# ESP32-S31 register map
Vendor: ESPRESSIF SYSTEMS (SHANGHAI) CO., LTD.; Series: ESP32 S-Series; File version: 1
CPU: RV32IMAFC r0p0, little endian, no MPU, FPU, 0 interrupt priority bits
Address unit: 32 bits
Registers are 32-bit, read-write, reset 0x0 unless marked. A register's access mark holds for its fields unless they carry their own. Offsets are from the block's base; [hi:lo] are bit positions; lines under a group give offsets from that group; {n}, {i} and the like mark numbered series.

## SOC_ETM (part 1 of 4) — Event Task Matrix
Base 0x20393000
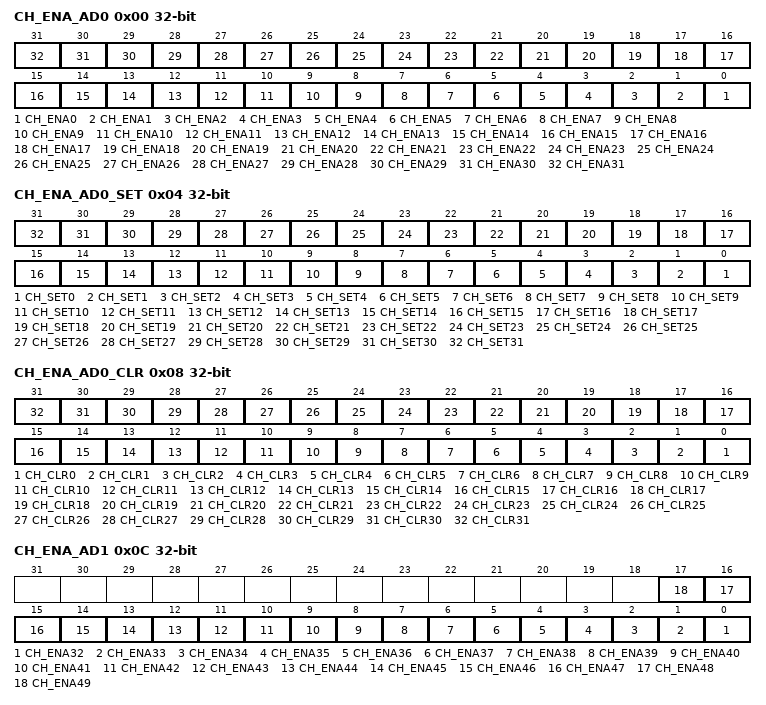
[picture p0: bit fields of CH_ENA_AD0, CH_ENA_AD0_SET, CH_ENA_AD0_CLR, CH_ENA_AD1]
0x00 CH_ENA_AD0 — Channel enable status register
  [n] CH_ENA{n} (n=0..31) — Represents ch{n} enable status.\\0: Disable\\1: Enable
0x04 CH_ENA_AD0_SET wo — Channel enable set register
  [n] CH_SET{n} (n=0..31) — Configures whether or not to enable ch{n}.\\0: Invalid, No effect\\1: Enable
0x08 CH_ENA_AD0_CLR wo — Channel enable clear register
  [n] CH_CLR{n} (n=0..31) — Configures whether or not to clear ch{n} enable.\\0: Invalid, No effect\\1: Clear
0x0C CH_ENA_AD1 — Channel enable status register
  [n-32] CH_ENA{n} (n=32..49) — Represents ch{n} enable status.\\0: Disable\\1: Enable
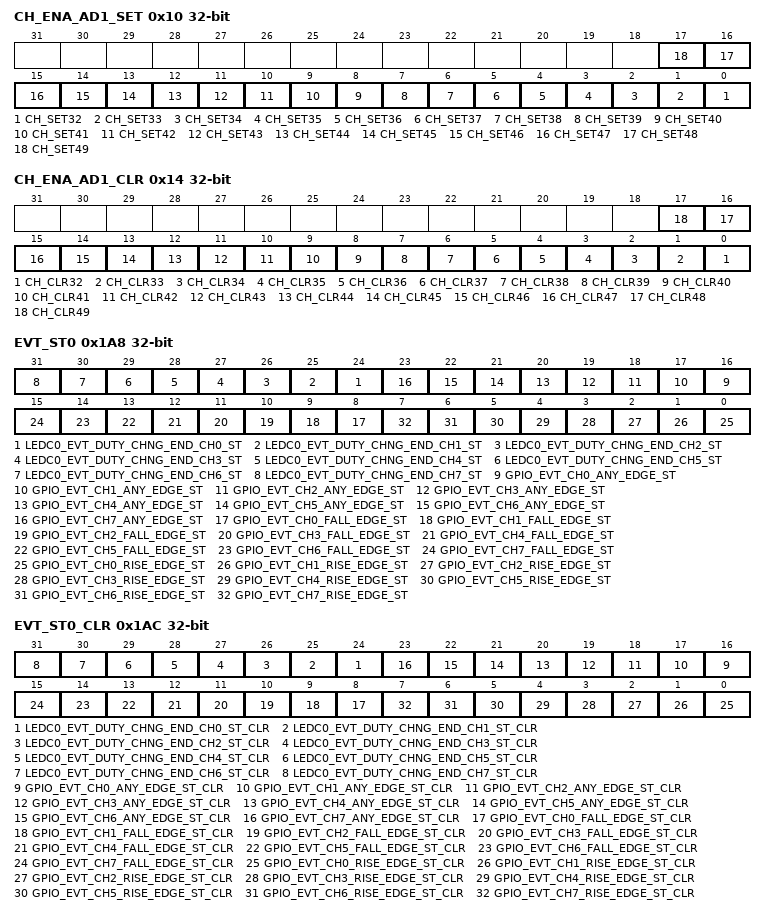
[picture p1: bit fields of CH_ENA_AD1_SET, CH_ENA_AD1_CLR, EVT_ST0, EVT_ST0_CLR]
0x10 CH_ENA_AD1_SET wo — Channel enable set register
  [n-32] CH_SET{n} (n=32..49) — Configures whether or not to enable ch{n}.\\0: Invalid, No effect\\1: Enable
0x14 CH_ENA_AD1_CLR wo — Channel enable clear register
  [n-32] CH_CLR{n} (n=32..49) — Configures whether or not to clear ch{n} enable.\\0: Invalid, No effect\\1: Clear
{0x18+8i} CH{i} (i=0..49) group — Cluster CH{i}, containing CH*_EVT_ID, CH*_TASK_ID
  0x00 EVT_ID — Channel0 event id register
    [8:0] EVT_ID — Configures ch%s_evt_id
  0x04 TASK_ID — Channel0 task id register
    [8:0] TASK_ID — Configures ch%s_task_id
0x1A8 EVT_ST0 — Events trigger status register
  [n+24] LEDC0_EVT_DUTY_CHNG_END_CH{n}_ST (n=0..7) — Represents LEDC0_evt_duty_chng_end_ch{n} trigger status.\\0: Not triggered\\1: Triggered
  [n+16] GPIO_EVT_CH{n}_ANY_EDGE_ST (n=0..7) — Represents GPIO_evt_ch{n}_any_edge trigger status.\\0: Not triggered\\1: Triggered
  [n+8] GPIO_EVT_CH{n}_FALL_EDGE_ST (n=0..7) — Represents GPIO_evt_ch{n}_fall_edge trigger status.\\0: Not triggered\\1: Triggered
  [n] GPIO_EVT_CH{n}_RISE_EDGE_ST (n=0..7) — Represents GPIO_evt_ch{n}_rise_edge trigger status.\\0: Not triggered\\1: Triggered
0x1AC EVT_ST0_CLR wo — Events trigger status clear register
  [n+24] LEDC0_EVT_DUTY_CHNG_END_CH{n}_ST_CLR (n=0..7) — Configures whether or not to clear LEDC0_evt_duty_chng_end_ch{n} trigger status.\\0: Invalid, No effect\\1: Clear
  [n+16] GPIO_EVT_CH{n}_ANY_EDGE_ST_CLR (n=0..7) — Configures whether or not to clear GPIO_evt_ch{n}_any_edge trigger status.\\0: Invalid, No effect\\1: Clear
  [n+8] GPIO_EVT_CH{n}_FALL_EDGE_ST_CLR (n=0..7) — Configures whether or not to clear GPIO_evt_ch{n}_fall_edge trigger status.\\0: Invalid, No effect\\1: Clear
  [n] GPIO_EVT_CH{n}_RISE_EDGE_ST_CLR (n=0..7) — Configures whether or not to clear GPIO_evt_ch{n}_rise_edge trigger status.\\0: Invalid, No effect\\1: Clear
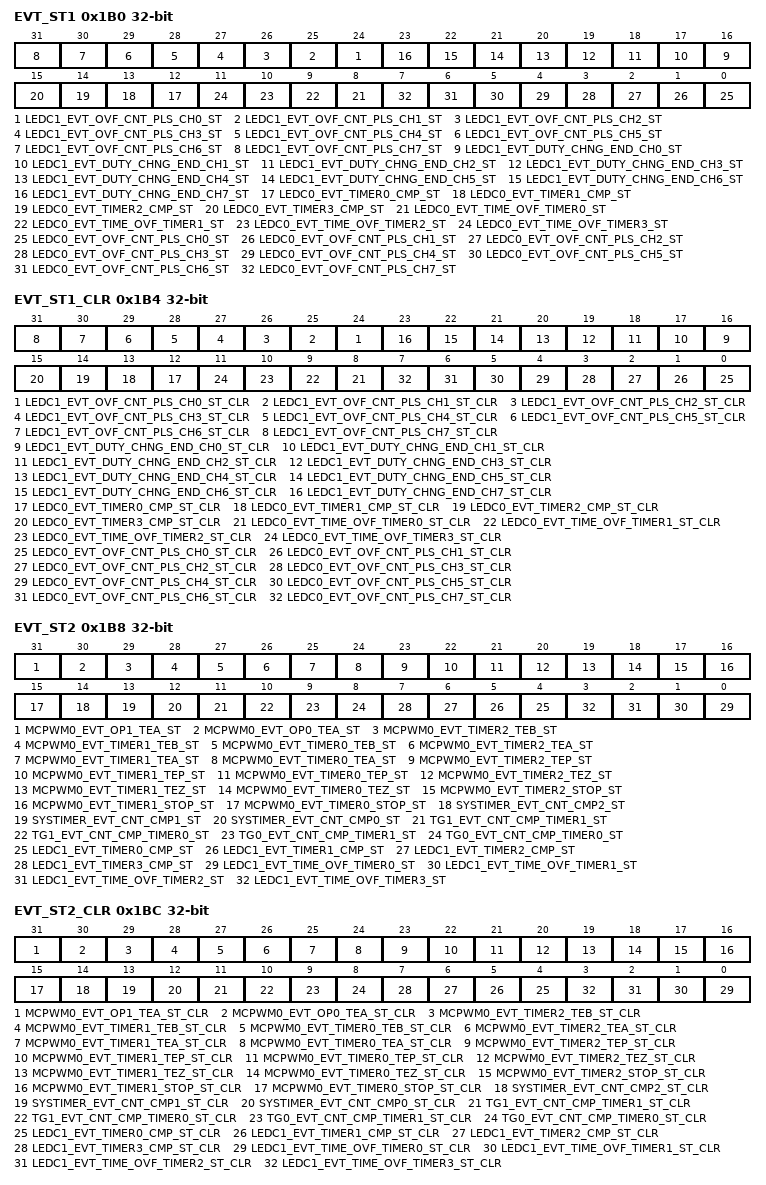
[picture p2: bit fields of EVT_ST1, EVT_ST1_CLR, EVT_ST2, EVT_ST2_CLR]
0x1B0 EVT_ST1 — Events trigger status register
  [n+24] LEDC1_EVT_OVF_CNT_PLS_CH{n}_ST (n=0..7) — Represents LEDC1_evt_ovf_cnt_pls_ch{n} trigger status.\\0: Not triggered\\1: Triggered
  [n+16] LEDC1_EVT_DUTY_CHNG_END_CH{n}_ST (n=0..7) — Represents LEDC1_evt_duty_chng_end_ch{n} trigger status.\\0: Not triggered\\1: Triggered
  [n+12] LEDC0_EVT_TIMER{n}_CMP_ST (n=0..3) — Represents LEDC0_evt_timer{n}_cmp trigger status.\\0: Not triggered\\1: Triggered
  [n+8] LEDC0_EVT_TIME_OVF_TIMER{n}_ST (n=0..3) — Represents LEDC0_evt_time_ovf_timer{n} trigger status.\\0: Not triggered\\1: Triggered
  [n] LEDC0_EVT_OVF_CNT_PLS_CH{n}_ST (n=0..7) — Represents LEDC0_evt_ovf_cnt_pls_ch{n} trigger status.\\0: Not triggered\\1: Triggered
0x1B4 EVT_ST1_CLR wo — Events trigger status clear register
  [n+24] LEDC1_EVT_OVF_CNT_PLS_CH{n}_ST_CLR (n=0..7) — Configures whether or not to clear LEDC1_evt_ovf_cnt_pls_ch{n} trigger status.\\0: Invalid, No effect\\1: Clear
  [n+16] LEDC1_EVT_DUTY_CHNG_END_CH{n}_ST_CLR (n=0..7) — Configures whether or not to clear LEDC1_evt_duty_chng_end_ch{n} trigger status.\\0: Invalid, No effect\\1: Clear
  [n+12] LEDC0_EVT_TIMER{n}_CMP_ST_CLR (n=0..3) — Configures whether or not to clear LEDC0_evt_timer{n}_cmp trigger status.\\0: Invalid, No effect\\1: Clear
  [n+8] LEDC0_EVT_TIME_OVF_TIMER{n}_ST_CLR (n=0..3) — Configures whether or not to clear LEDC0_evt_time_ovf_timer{n} trigger status.\\0: Invalid, No effect\\1: Clear
  [n] LEDC0_EVT_OVF_CNT_PLS_CH{n}_ST_CLR (n=0..7) — Configures whether or not to clear LEDC0_evt_ovf_cnt_pls_ch{n} trigger status.\\0: Invalid, No effect\\1: Clear
0x1B8 EVT_ST2 — Events trigger status register
  [31] MCPWM0_EVT_OP1_TEA_ST — Represents MCPWM0_evt_op1_tea trigger status.\\0: Not triggered\\1: Triggered
  [30] MCPWM0_EVT_OP0_TEA_ST — Represents MCPWM0_evt_op0_tea trigger status.\\0: Not triggered\\1: Triggered
  [29] MCPWM0_EVT_TIMER2_TEB_ST — Represents MCPWM0_evt_timer2_teb trigger status.\\0: Not triggered\\1: Triggered
  [28] MCPWM0_EVT_TIMER1_TEB_ST — Represents MCPWM0_evt_timer1_teb trigger status.\\0: Not triggered\\1: Triggered
  [27] MCPWM0_EVT_TIMER0_TEB_ST — Represents MCPWM0_evt_timer0_teb trigger status.\\0: Not triggered\\1: Triggered
  [26] MCPWM0_EVT_TIMER2_TEA_ST — Represents MCPWM0_evt_timer2_tea trigger status.\\0: Not triggered\\1: Triggered
  [25] MCPWM0_EVT_TIMER1_TEA_ST — Represents MCPWM0_evt_timer1_tea trigger status.\\0: Not triggered\\1: Triggered
  [24] MCPWM0_EVT_TIMER0_TEA_ST — Represents MCPWM0_evt_timer0_tea trigger status.\\0: Not triggered\\1: Triggered
  [23] MCPWM0_EVT_TIMER2_TEP_ST — Represents MCPWM0_evt_timer2_tep trigger status.\\0: Not triggered\\1: Triggered
  [22] MCPWM0_EVT_TIMER1_TEP_ST — Represents MCPWM0_evt_timer1_tep trigger status.\\0: Not triggered\\1: Triggered
  [21] MCPWM0_EVT_TIMER0_TEP_ST — Represents MCPWM0_evt_timer0_tep trigger status.\\0: Not triggered\\1: Triggered
  [20] MCPWM0_EVT_TIMER2_TEZ_ST — Represents MCPWM0_evt_timer2_tez trigger status.\\0: Not triggered\\1: Triggered
  [19] MCPWM0_EVT_TIMER1_TEZ_ST — Represents MCPWM0_evt_timer1_tez trigger status.\\0: Not triggered\\1: Triggered
  [18] MCPWM0_EVT_TIMER0_TEZ_ST — Represents MCPWM0_evt_timer0_tez trigger status.\\0: Not triggered\\1: Triggered
  [17] MCPWM0_EVT_TIMER2_STOP_ST — Represents MCPWM0_evt_timer2_stop trigger status.\\0: Not triggered\\1: Triggered
  [16] MCPWM0_EVT_TIMER1_STOP_ST — Represents MCPWM0_evt_timer1_stop trigger status.\\0: Not triggered\\1: Triggered
  [15] MCPWM0_EVT_TIMER0_STOP_ST — Represents MCPWM0_evt_timer0_stop trigger status.\\0: Not triggered\\1: Triggered
  [14] SYSTIMER_EVT_CNT_CMP2_ST — Represents SYSTIMER_evt_cnt_cmp2 trigger status.\\0: Not triggered\\1: Triggered
  [13] SYSTIMER_EVT_CNT_CMP1_ST — Represents SYSTIMER_evt_cnt_cmp1 trigger status.\\0: Not triggered\\1: Triggered
  [12] SYSTIMER_EVT_CNT_CMP0_ST — Represents SYSTIMER_evt_cnt_cmp0 trigger status.\\0: Not triggered\\1: Triggered
  [11] TG1_EVT_CNT_CMP_TIMER1_ST — Represents TG1_evt_cnt_cmp_timer1 trigger status.\\0: Not triggered\\1: Triggered
  [10] TG1_EVT_CNT_CMP_TIMER0_ST — Represents TG1_evt_cnt_cmp_timer0 trigger status.\\0: Not triggered\\1: Triggered
  [9] TG0_EVT_CNT_CMP_TIMER1_ST — Represents TG0_evt_cnt_cmp_timer1 trigger status.\\0: Not triggered\\1: Triggered
  [8] TG0_EVT_CNT_CMP_TIMER0_ST — Represents TG0_evt_cnt_cmp_timer0 trigger status.\\0: Not triggered\\1: Triggered
  [n+4] LEDC1_EVT_TIMER{n}_CMP_ST (n=0..3) — Represents LEDC1_evt_timer{n}_cmp trigger status.\\0: Not triggered\\1: Triggered
  [n] LEDC1_EVT_TIME_OVF_TIMER{n}_ST (n=0..3) — Represents LEDC1_evt_time_ovf_timer{n} trigger status.\\0: Not triggered\\1: Triggered
0x1BC EVT_ST2_CLR wo — Events trigger status clear register
  [31] MCPWM0_EVT_OP1_TEA_ST_CLR — Configures whether or not to clear MCPWM0_evt_op1_tea trigger status.\\0: Invalid, No effect\\1: Clear
  [30] MCPWM0_EVT_OP0_TEA_ST_CLR — Configures whether or not to clear MCPWM0_evt_op0_tea trigger status.\\0: Invalid, No effect\\1: Clear
  [29] MCPWM0_EVT_TIMER2_TEB_ST_CLR — Configures whether or not to clear MCPWM0_evt_timer2_teb trigger status.\\0: Invalid, No effect\\1: Clear
  [28] MCPWM0_EVT_TIMER1_TEB_ST_CLR — Configures whether or not to clear MCPWM0_evt_timer1_teb trigger status.\\0: Invalid, No effect\\1: Clear
  [27] MCPWM0_EVT_TIMER0_TEB_ST_CLR — Configures whether or not to clear MCPWM0_evt_timer0_teb trigger status.\\0: Invalid, No effect\\1: Clear
  [26] MCPWM0_EVT_TIMER2_TEA_ST_CLR — Configures whether or not to clear MCPWM0_evt_timer2_tea trigger status.\\0: Invalid, No effect\\1: Clear
  [25] MCPWM0_EVT_TIMER1_TEA_ST_CLR — Configures whether or not to clear MCPWM0_evt_timer1_tea trigger status.\\0: Invalid, No effect\\1: Clear
  [24] MCPWM0_EVT_TIMER0_TEA_ST_CLR — Configures whether or not to clear MCPWM0_evt_timer0_tea trigger status.\\0: Invalid, No effect\\1: Clear
  [23] MCPWM0_EVT_TIMER2_TEP_ST_CLR — Configures whether or not to clear MCPWM0_evt_timer2_tep trigger status.\\0: Invalid, No effect\\1: Clear
  [22] MCPWM0_EVT_TIMER1_TEP_ST_CLR — Configures whether or not to clear MCPWM0_evt_timer1_tep trigger status.\\0: Invalid, No effect\\1: Clear
  [21] MCPWM0_EVT_TIMER0_TEP_ST_CLR — Configures whether or not to clear MCPWM0_evt_timer0_tep trigger status.\\0: Invalid, No effect\\1: Clear
  [20] MCPWM0_EVT_TIMER2_TEZ_ST_CLR — Configures whether or not to clear MCPWM0_evt_timer2_tez trigger status.\\0: Invalid, No effect\\1: Clear
  [19] MCPWM0_EVT_TIMER1_TEZ_ST_CLR — Configures whether or not to clear MCPWM0_evt_timer1_tez trigger status.\\0: Invalid, No effect\\1: Clear
  [18] MCPWM0_EVT_TIMER0_TEZ_ST_CLR — Configures whether or not to clear MCPWM0_evt_timer0_tez trigger status.\\0: Invalid, No effect\\1: Clear
  [17] MCPWM0_EVT_TIMER2_STOP_ST_CLR — Configures whether or not to clear MCPWM0_evt_timer2_stop trigger status.\\0: Invalid, No effect\\1: Clear
  [16] MCPWM0_EVT_TIMER1_STOP_ST_CLR — Configures whether or not to clear MCPWM0_evt_timer1_stop trigger status.\\0: Invalid, No effect\\1: Clear
  [15] MCPWM0_EVT_TIMER0_STOP_ST_CLR — Configures whether or not to clear MCPWM0_evt_timer0_stop trigger status.\\0: Invalid, No effect\\1: Clear
  [14] SYSTIMER_EVT_CNT_CMP2_ST_CLR — Configures whether or not to clear SYSTIMER_evt_cnt_cmp2 trigger status.\\0: Invalid, No effect\\1: Clear
  [13] SYSTIMER_EVT_CNT_CMP1_ST_CLR — Configures whether or not to clear SYSTIMER_evt_cnt_cmp1 trigger status.\\0: Invalid, No effect\\1: Clear
  [12] SYSTIMER_EVT_CNT_CMP0_ST_CLR — Configures whether or not to clear SYSTIMER_evt_cnt_cmp0 trigger status.\\0: Invalid, No effect\\1: Clear
  [11] TG1_EVT_CNT_CMP_TIMER1_ST_CLR — Configures whether or not to clear TG1_evt_cnt_cmp_timer1 trigger status.\\0: Invalid, No effect\\1: Clear
  [10] TG1_EVT_CNT_CMP_TIMER0_ST_CLR — Configures whether or not to clear TG1_evt_cnt_cmp_timer0 trigger status.\\0: Invalid, No effect\\1: Clear
  [9] TG0_EVT_CNT_CMP_TIMER1_ST_CLR — Configures whether or not to clear TG0_evt_cnt_cmp_timer1 trigger status.\\0: Invalid, No effect\\1: Clear
  [8] TG0_EVT_CNT_CMP_TIMER0_ST_CLR — Configures whether or not to clear TG0_evt_cnt_cmp_timer0 trigger status.\\0: Invalid, No effect\\1: Clear
  [n+4] LEDC1_EVT_TIMER{n}_CMP_ST_CLR (n=0..3) — Configures whether or not to clear LEDC1_evt_timer{n}_cmp trigger status.\\0: Invalid, No effect\\1: Clear
  [n] LEDC1_EVT_TIME_OVF_TIMER{n}_ST_CLR (n=0..3) — Configures whether or not to clear LEDC1_evt_time_ovf_timer{n} trigger status.\\0: Invalid, No effect\\1: Clear
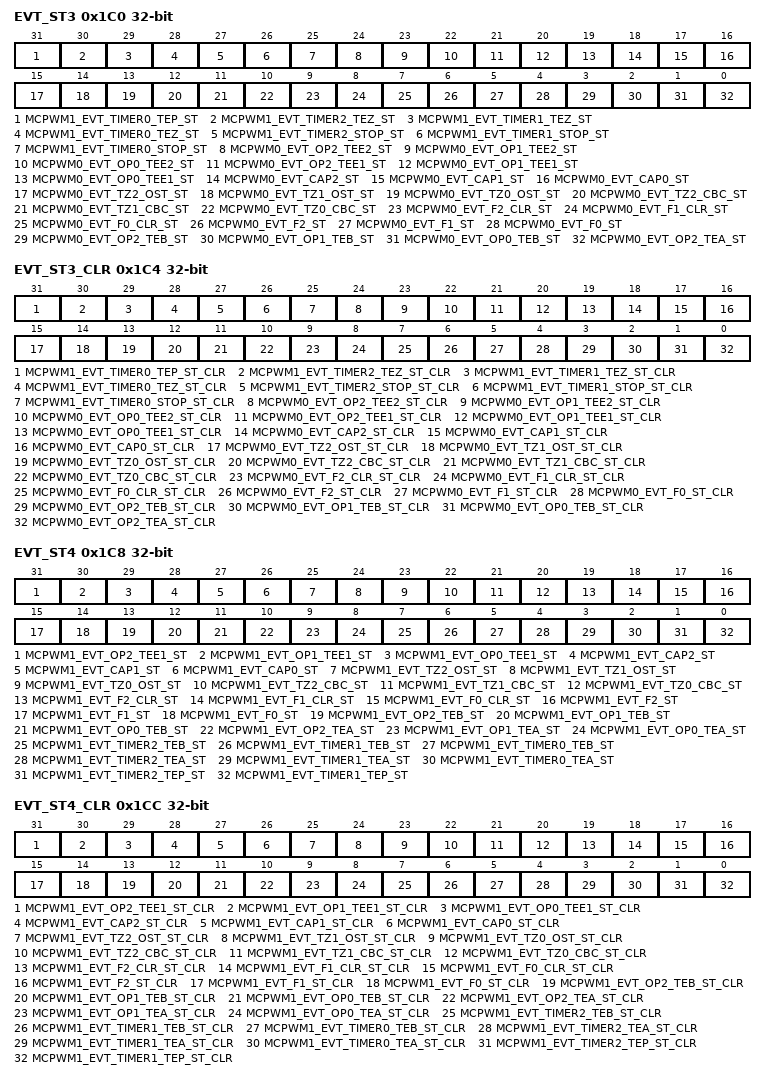
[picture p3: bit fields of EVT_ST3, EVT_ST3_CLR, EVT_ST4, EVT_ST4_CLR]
0x1C0 EVT_ST3 — Events trigger status register
  [31] MCPWM1_EVT_TIMER0_TEP_ST — Represents MCPWM1_evt_timer0_tep trigger status.\\0: Not triggered\\1: Triggered
  [30] MCPWM1_EVT_TIMER2_TEZ_ST — Represents MCPWM1_evt_timer2_tez trigger status.\\0: Not triggered\\1: Triggered
  [29] MCPWM1_EVT_TIMER1_TEZ_ST — Represents MCPWM1_evt_timer1_tez trigger status.\\0: Not triggered\\1: Triggered
  [28] MCPWM1_EVT_TIMER0_TEZ_ST — Represents MCPWM1_evt_timer0_tez trigger status.\\0: Not triggered\\1: Triggered
  [27] MCPWM1_EVT_TIMER2_STOP_ST — Represents MCPWM1_evt_timer2_stop trigger status.\\0: Not triggered\\1: Triggered
  [26] MCPWM1_EVT_TIMER1_STOP_ST — Represents MCPWM1_evt_timer1_stop trigger status.\\0: Not triggered\\1: Triggered
  [25] MCPWM1_EVT_TIMER0_STOP_ST — Represents MCPWM1_evt_timer0_stop trigger status.\\0: Not triggered\\1: Triggered
  [24] MCPWM0_EVT_OP2_TEE2_ST — Represents MCPWM0_evt_op2_tee2 trigger status.\\0: Not triggered\\1: Triggered
  [23] MCPWM0_EVT_OP1_TEE2_ST — Represents MCPWM0_evt_op1_tee2 trigger status.\\0: Not triggered\\1: Triggered
  [22] MCPWM0_EVT_OP0_TEE2_ST — Represents MCPWM0_evt_op0_tee2 trigger status.\\0: Not triggered\\1: Triggered
  [21] MCPWM0_EVT_OP2_TEE1_ST — Represents MCPWM0_evt_op2_tee1 trigger status.\\0: Not triggered\\1: Triggered
  [20] MCPWM0_EVT_OP1_TEE1_ST — Represents MCPWM0_evt_op1_tee1 trigger status.\\0: Not triggered\\1: Triggered
  [19] MCPWM0_EVT_OP0_TEE1_ST — Represents MCPWM0_evt_op0_tee1 trigger status.\\0: Not triggered\\1: Triggered
  [18] MCPWM0_EVT_CAP2_ST — Represents MCPWM0_evt_cap2 trigger status.\\0: Not triggered\\1: Triggered
  [17] MCPWM0_EVT_CAP1_ST — Represents MCPWM0_evt_cap1 trigger status.\\0: Not triggered\\1: Triggered
  [16] MCPWM0_EVT_CAP0_ST — Represents MCPWM0_evt_cap0 trigger status.\\0: Not triggered\\1: Triggered
  [15] MCPWM0_EVT_TZ2_OST_ST — Represents MCPWM0_evt_tz2_ost trigger status.\\0: Not triggered\\1: Triggered
  [14] MCPWM0_EVT_TZ1_OST_ST — Represents MCPWM0_evt_tz1_ost trigger status.\\0: Not triggered\\1: Triggered
  [13] MCPWM0_EVT_TZ0_OST_ST — Represents MCPWM0_evt_tz0_ost trigger status.\\0: Not triggered\\1: Triggered
  [12] MCPWM0_EVT_TZ2_CBC_ST — Represents MCPWM0_evt_tz2_cbc trigger status.\\0: Not triggered\\1: Triggered
  [11] MCPWM0_EVT_TZ1_CBC_ST — Represents MCPWM0_evt_tz1_cbc trigger status.\\0: Not triggered\\1: Triggered
  [10] MCPWM0_EVT_TZ0_CBC_ST — Represents MCPWM0_evt_tz0_cbc trigger status.\\0: Not triggered\\1: Triggered
  [9] MCPWM0_EVT_F2_CLR_ST — Represents MCPWM0_evt_f2_clr trigger status.\\0: Not triggered\\1: Triggered
  [8] MCPWM0_EVT_F1_CLR_ST — Represents MCPWM0_evt_f1_clr trigger status.\\0: Not triggered\\1: Triggered
  [7] MCPWM0_EVT_F0_CLR_ST — Represents MCPWM0_evt_f0_clr trigger status.\\0: Not triggered\\1: Triggered
  [6] MCPWM0_EVT_F2_ST — Represents MCPWM0_evt_f2 trigger status.\\0: Not triggered\\1: Triggered
  [5] MCPWM0_EVT_F1_ST — Represents MCPWM0_evt_f1 trigger status.\\0: Not triggered\\1: Triggered
  [4] MCPWM0_EVT_F0_ST — Represents MCPWM0_evt_f0 trigger status.\\0: Not triggered\\1: Triggered
  [3] MCPWM0_EVT_OP2_TEB_ST — Represents MCPWM0_evt_op2_teb trigger status.\\0: Not triggered\\1: Triggered
  [2] MCPWM0_EVT_OP1_TEB_ST — Represents MCPWM0_evt_op1_teb trigger status.\\0: Not triggered\\1: Triggered
  [1] MCPWM0_EVT_OP0_TEB_ST — Represents MCPWM0_evt_op0_teb trigger status.\\0: Not triggered\\1: Triggered
  [0] MCPWM0_EVT_OP2_TEA_ST — Represents MCPWM0_evt_op2_tea trigger status.\\0: Not triggered\\1: Triggered
0x1C4 EVT_ST3_CLR wo — Events trigger status clear register
  [31] MCPWM1_EVT_TIMER0_TEP_ST_CLR — Configures whether or not to clear MCPWM1_evt_timer0_tep trigger status.\\0: Invalid, No effect\\1: Clear
  [30] MCPWM1_EVT_TIMER2_TEZ_ST_CLR — Configures whether or not to clear MCPWM1_evt_timer2_tez trigger status.\\0: Invalid, No effect\\1: Clear
  [29] MCPWM1_EVT_TIMER1_TEZ_ST_CLR — Configures whether or not to clear MCPWM1_evt_timer1_tez trigger status.\\0: Invalid, No effect\\1: Clear
  [28] MCPWM1_EVT_TIMER0_TEZ_ST_CLR — Configures whether or not to clear MCPWM1_evt_timer0_tez trigger status.\\0: Invalid, No effect\\1: Clear
  [27] MCPWM1_EVT_TIMER2_STOP_ST_CLR — Configures whether or not to clear MCPWM1_evt_timer2_stop trigger status.\\0: Invalid, No effect\\1: Clear
  [26] MCPWM1_EVT_TIMER1_STOP_ST_CLR — Configures whether or not to clear MCPWM1_evt_timer1_stop trigger status.\\0: Invalid, No effect\\1: Clear
  [25] MCPWM1_EVT_TIMER0_STOP_ST_CLR — Configures whether or not to clear MCPWM1_evt_timer0_stop trigger status.\\0: Invalid, No effect\\1: Clear
  [24] MCPWM0_EVT_OP2_TEE2_ST_CLR — Configures whether or not to clear MCPWM0_evt_op2_tee2 trigger status.\\0: Invalid, No effect\\1: Clear
  [23] MCPWM0_EVT_OP1_TEE2_ST_CLR — Configures whether or not to clear MCPWM0_evt_op1_tee2 trigger status.\\0: Invalid, No effect\\1: Clear
  [22] MCPWM0_EVT_OP0_TEE2_ST_CLR — Configures whether or not to clear MCPWM0_evt_op0_tee2 trigger status.\\0: Invalid, No effect\\1: Clear
  [21] MCPWM0_EVT_OP2_TEE1_ST_CLR — Configures whether or not to clear MCPWM0_evt_op2_tee1 trigger status.\\0: Invalid, No effect\\1: Clear
  [20] MCPWM0_EVT_OP1_TEE1_ST_CLR — Configures whether or not to clear MCPWM0_evt_op1_tee1 trigger status.\\0: Invalid, No effect\\1: Clear
  [19] MCPWM0_EVT_OP0_TEE1_ST_CLR — Configures whether or not to clear MCPWM0_evt_op0_tee1 trigger status.\\0: Invalid, No effect\\1: Clear
  [18] MCPWM0_EVT_CAP2_ST_CLR — Configures whether or not to clear MCPWM0_evt_cap2 trigger status.\\0: Invalid, No effect\\1: Clear
  [17] MCPWM0_EVT_CAP1_ST_CLR — Configures whether or not to clear MCPWM0_evt_cap1 trigger status.\\0: Invalid, No effect\\1: Clear
  [16] MCPWM0_EVT_CAP0_ST_CLR — Configures whether or not to clear MCPWM0_evt_cap0 trigger status.\\0: Invalid, No effect\\1: Clear
  [15] MCPWM0_EVT_TZ2_OST_ST_CLR — Configures whether or not to clear MCPWM0_evt_tz2_ost trigger status.\\0: Invalid, No effect\\1: Clear
  [14] MCPWM0_EVT_TZ1_OST_ST_CLR — Configures whether or not to clear MCPWM0_evt_tz1_ost trigger status.\\0: Invalid, No effect\\1: Clear
  [13] MCPWM0_EVT_TZ0_OST_ST_CLR — Configures whether or not to clear MCPWM0_evt_tz0_ost trigger status.\\0: Invalid, No effect\\1: Clear
  [12] MCPWM0_EVT_TZ2_CBC_ST_CLR — Configures whether or not to clear MCPWM0_evt_tz2_cbc trigger status.\\0: Invalid, No effect\\1: Clear
  [11] MCPWM0_EVT_TZ1_CBC_ST_CLR — Configures whether or not to clear MCPWM0_evt_tz1_cbc trigger status.\\0: Invalid, No effect\\1: Clear
  [10] MCPWM0_EVT_TZ0_CBC_ST_CLR — Configures whether or not to clear MCPWM0_evt_tz0_cbc trigger status.\\0: Invalid, No effect\\1: Clear
  [9] MCPWM0_EVT_F2_CLR_ST_CLR — Configures whether or not to clear MCPWM0_evt_f2_clr trigger status.\\0: Invalid, No effect\\1: Clear
  [8] MCPWM0_EVT_F1_CLR_ST_CLR — Configures whether or not to clear MCPWM0_evt_f1_clr trigger status.\\0: Invalid, No effect\\1: Clear
  [7] MCPWM0_EVT_F0_CLR_ST_CLR — Configures whether or not to clear MCPWM0_evt_f0_clr trigger status.\\0: Invalid, No effect\\1: Clear
  [6] MCPWM0_EVT_F2_ST_CLR — Configures whether or not to clear MCPWM0_evt_f2 trigger status.\\0: Invalid, No effect\\1: Clear
  [5] MCPWM0_EVT_F1_ST_CLR — Configures whether or not to clear MCPWM0_evt_f1 trigger status.\\0: Invalid, No effect\\1: Clear
  [4] MCPWM0_EVT_F0_ST_CLR — Configures whether or not to clear MCPWM0_evt_f0 trigger status.\\0: Invalid, No effect\\1: Clear
  [3] MCPWM0_EVT_OP2_TEB_ST_CLR — Configures whether or not to clear MCPWM0_evt_op2_teb trigger status.\\0: Invalid, No effect\\1: Clear
  [2] MCPWM0_EVT_OP1_TEB_ST_CLR — Configures whether or not to clear MCPWM0_evt_op1_teb trigger status.\\0: Invalid, No effect\\1: Clear
  [1] MCPWM0_EVT_OP0_TEB_ST_CLR — Configures whether or not to clear MCPWM0_evt_op0_teb trigger status.\\0: Invalid, No effect\\1: Clear
  [0] MCPWM0_EVT_OP2_TEA_ST_CLR — Configures whether or not to clear MCPWM0_evt_op2_tea trigger status.\\0: Invalid, No effect\\1: Clear
0x1C8 EVT_ST4 — Events trigger status register
  [31] MCPWM1_EVT_OP2_TEE1_ST — Represents MCPWM1_evt_op2_tee1 trigger status.\\0: Not triggered\\1: Triggered
  [30] MCPWM1_EVT_OP1_TEE1_ST — Represents MCPWM1_evt_op1_tee1 trigger status.\\0: Not triggered\\1: Triggered
  [29] MCPWM1_EVT_OP0_TEE1_ST — Represents MCPWM1_evt_op0_tee1 trigger status.\\0: Not triggered\\1: Triggered
  [28] MCPWM1_EVT_CAP2_ST — Represents MCPWM1_evt_cap2 trigger status.\\0: Not triggered\\1: Triggered
  [27] MCPWM1_EVT_CAP1_ST — Represents MCPWM1_evt_cap1 trigger status.\\0: Not triggered\\1: Triggered
  [26] MCPWM1_EVT_CAP0_ST — Represents MCPWM1_evt_cap0 trigger status.\\0: Not triggered\\1: Triggered
  [25] MCPWM1_EVT_TZ2_OST_ST — Represents MCPWM1_evt_tz2_ost trigger status.\\0: Not triggered\\1: Triggered
  [24] MCPWM1_EVT_TZ1_OST_ST — Represents MCPWM1_evt_tz1_ost trigger status.\\0: Not triggered\\1: Triggered
  [23] MCPWM1_EVT_TZ0_OST_ST — Represents MCPWM1_evt_tz0_ost trigger status.\\0: Not triggered\\1: Triggered
  [22] MCPWM1_EVT_TZ2_CBC_ST — Represents MCPWM1_evt_tz2_cbc trigger status.\\0: Not triggered\\1: Triggered
  [21] MCPWM1_EVT_TZ1_CBC_ST — Represents MCPWM1_evt_tz1_cbc trigger status.\\0: Not triggered\\1: Triggered
  [20] MCPWM1_EVT_TZ0_CBC_ST — Represents MCPWM1_evt_tz0_cbc trigger status.\\0: Not triggered\\1: Triggered
  [19] MCPWM1_EVT_F2_CLR_ST — Represents MCPWM1_evt_f2_clr trigger status.\\0: Not triggered\\1: Triggered
  [18] MCPWM1_EVT_F1_CLR_ST — Represents MCPWM1_evt_f1_clr trigger status.\\0: Not triggered\\1: Triggered
  [17] MCPWM1_EVT_F0_CLR_ST — Represents MCPWM1_evt_f0_clr trigger status.\\0: Not triggered\\1: Triggered
  [16] MCPWM1_EVT_F2_ST — Represents MCPWM1_evt_f2 trigger status.\\0: Not triggered\\1: Triggered
  [15] MCPWM1_EVT_F1_ST — Represents MCPWM1_evt_f1 trigger status.\\0: Not triggered\\1: Triggered
  [14] MCPWM1_EVT_F0_ST — Represents MCPWM1_evt_f0 trigger status.\\0: Not triggered\\1: Triggered
  [13] MCPWM1_EVT_OP2_TEB_ST — Represents MCPWM1_evt_op2_teb trigger status.\\0: Not triggered\\1: Triggered
  [12] MCPWM1_EVT_OP1_TEB_ST — Represents MCPWM1_evt_op1_teb trigger status.\\0: Not triggered\\1: Triggered
  [11] MCPWM1_EVT_OP0_TEB_ST — Represents MCPWM1_evt_op0_teb trigger status.\\0: Not triggered\\1: Triggered
  [10] MCPWM1_EVT_OP2_TEA_ST — Represents MCPWM1_evt_op2_tea trigger status.\\0: Not triggered\\1: Triggered
  [9] MCPWM1_EVT_OP1_TEA_ST — Represents MCPWM1_evt_op1_tea trigger status.\\0: Not triggered\\1: Triggered
  [8] MCPWM1_EVT_OP0_TEA_ST — Represents MCPWM1_evt_op0_tea trigger status.\\0: Not triggered\\1: Triggered
  [7] MCPWM1_EVT_TIMER2_TEB_ST — Represents MCPWM1_evt_timer2_teb trigger status.\\0: Not triggered\\1: Triggered
  [6] MCPWM1_EVT_TIMER1_TEB_ST — Represents MCPWM1_evt_timer1_teb trigger status.\\0: Not triggered\\1: Triggered
  [5] MCPWM1_EVT_TIMER0_TEB_ST — Represents MCPWM1_evt_timer0_teb trigger status.\\0: Not triggered\\1: Triggered
  [4] MCPWM1_EVT_TIMER2_TEA_ST — Represents MCPWM1_evt_timer2_tea trigger status.\\0: Not triggered\\1: Triggered
  [3] MCPWM1_EVT_TIMER1_TEA_ST — Represents MCPWM1_evt_timer1_tea trigger status.\\0: Not triggered\\1: Triggered
  [2] MCPWM1_EVT_TIMER0_TEA_ST — Represents MCPWM1_evt_timer0_tea trigger status.\\0: Not triggered\\1: Triggered
  [1] MCPWM1_EVT_TIMER2_TEP_ST — Represents MCPWM1_evt_timer2_tep trigger status.\\0: Not triggered\\1: Triggered
  [0] MCPWM1_EVT_TIMER1_TEP_ST — Represents MCPWM1_evt_timer1_tep trigger status.\\0: Not triggered\\1: Triggered
0x1CC EVT_ST4_CLR wo — Events trigger status clear register
  [31] MCPWM1_EVT_OP2_TEE1_ST_CLR — Configures whether or not to clear MCPWM1_evt_op2_tee1 trigger status.\\0: Invalid, No effect\\1: Clear
  [30] MCPWM1_EVT_OP1_TEE1_ST_CLR — Configures whether or not to clear MCPWM1_evt_op1_tee1 trigger status.\\0: Invalid, No effect\\1: Clear
  [29] MCPWM1_EVT_OP0_TEE1_ST_CLR — Configures whether or not to clear MCPWM1_evt_op0_tee1 trigger status.\\0: Invalid, No effect\\1: Clear
  [28] MCPWM1_EVT_CAP2_ST_CLR — Configures whether or not to clear MCPWM1_evt_cap2 trigger status.\\0: Invalid, No effect\\1: Clear
  [27] MCPWM1_EVT_CAP1_ST_CLR — Configures whether or not to clear MCPWM1_evt_cap1 trigger status.\\0: Invalid, No effect\\1: Clear
  [26] MCPWM1_EVT_CAP0_ST_CLR — Configures whether or not to clear MCPWM1_evt_cap0 trigger status.\\0: Invalid, No effect\\1: Clear
  [25] MCPWM1_EVT_TZ2_OST_ST_CLR — Configures whether or not to clear MCPWM1_evt_tz2_ost trigger status.\\0: Invalid, No effect\\1: Clear
  [24] MCPWM1_EVT_TZ1_OST_ST_CLR — Configures whether or not to clear MCPWM1_evt_tz1_ost trigger status.\\0: Invalid, No effect\\1: Clear
  [23] MCPWM1_EVT_TZ0_OST_ST_CLR — Configures whether or not to clear MCPWM1_evt_tz0_ost trigger status.\\0: Invalid, No effect\\1: Clear
  [22] MCPWM1_EVT_TZ2_CBC_ST_CLR — Configures whether or not to clear MCPWM1_evt_tz2_cbc trigger status.\\0: Invalid, No effect\\1: Clear
  [21] MCPWM1_EVT_TZ1_CBC_ST_CLR — Configures whether or not to clear MCPWM1_evt_tz1_cbc trigger status.\\0: Invalid, No effect\\1: Clear
  [20] MCPWM1_EVT_TZ0_CBC_ST_CLR — Configures whether or not to clear MCPWM1_evt_tz0_cbc trigger status.\\0: Invalid, No effect\\1: Clear
  [19] MCPWM1_EVT_F2_CLR_ST_CLR — Configures whether or not to clear MCPWM1_evt_f2_clr trigger status.\\0: Invalid, No effect\\1: Clear
  [18] MCPWM1_EVT_F1_CLR_ST_CLR — Configures whether or not to clear MCPWM1_evt_f1_clr trigger status.\\0: Invalid, No effect\\1: Clear
  [17] MCPWM1_EVT_F0_CLR_ST_CLR — Configures whether or not to clear MCPWM1_evt_f0_clr trigger status.\\0: Invalid, No effect\\1: Clear
  [16] MCPWM1_EVT_F2_ST_CLR — Configures whether or not to clear MCPWM1_evt_f2 trigger status.\\0: Invalid, No effect\\1: Clear
  [15] MCPWM1_EVT_F1_ST_CLR — Configures whether or not to clear MCPWM1_evt_f1 trigger status.\\0: Invalid, No effect\\1: Clear
  [14] MCPWM1_EVT_F0_ST_CLR — Configures whether or not to clear MCPWM1_evt_f0 trigger status.\\0: Invalid, No effect\\1: Clear
  [13] MCPWM1_EVT_OP2_TEB_ST_CLR — Configures whether or not to clear MCPWM1_evt_op2_teb trigger status.\\0: Invalid, No effect\\1: Clear
  [12] MCPWM1_EVT_OP1_TEB_ST_CLR — Configures whether or not to clear MCPWM1_evt_op1_teb trigger status.\\0: Invalid, No effect\\1: Clear
  [11] MCPWM1_EVT_OP0_TEB_ST_CLR — Configures whether or not to clear MCPWM1_evt_op0_teb trigger status.\\0: Invalid, No effect\\1: Clear
  [10] MCPWM1_EVT_OP2_TEA_ST_CLR — Configures whether or not to clear MCPWM1_evt_op2_tea trigger status.\\0: Invalid, No effect\\1: Clear
  [9] MCPWM1_EVT_OP1_TEA_ST_CLR — Configures whether or not to clear MCPWM1_evt_op1_tea trigger status.\\0: Invalid, No effect\\1: Clear
  [8] MCPWM1_EVT_OP0_TEA_ST_CLR — Configures whether or not to clear MCPWM1_evt_op0_tea trigger status.\\0: Invalid, No effect\\1: Clear
  [7] MCPWM1_EVT_TIMER2_TEB_ST_CLR — Configures whether or not to clear MCPWM1_evt_timer2_teb trigger status.\\0: Invalid, No effect\\1: Clear
  [6] MCPWM1_EVT_TIMER1_TEB_ST_CLR — Configures whether or not to clear MCPWM1_evt_timer1_teb trigger status.\\0: Invalid, No effect\\1: Clear
  [5] MCPWM1_EVT_TIMER0_TEB_ST_CLR — Configures whether or not to clear MCPWM1_evt_timer0_teb trigger status.\\0: Invalid, No effect\\1: Clear
  [4] MCPWM1_EVT_TIMER2_TEA_ST_CLR — Configures whether or not to clear MCPWM1_evt_timer2_tea trigger status.\\0: Invalid, No effect\\1: Clear
  [3] MCPWM1_EVT_TIMER1_TEA_ST_CLR — Configures whether or not to clear MCPWM1_evt_timer1_tea trigger status.\\0: Invalid, No effect\\1: Clear
  [2] MCPWM1_EVT_TIMER0_TEA_ST_CLR — Configures whether or not to clear MCPWM1_evt_timer0_tea trigger status.\\0: Invalid, No effect\\1: Clear
  [1] MCPWM1_EVT_TIMER2_TEP_ST_CLR — Configures whether or not to clear MCPWM1_evt_timer2_tep trigger status.\\0: Invalid, No effect\\1: Clear
  [0] MCPWM1_EVT_TIMER1_TEP_ST_CLR — Configures whether or not to clear MCPWM1_evt_timer1_tep trigger status.\\0: Invalid, No effect\\1: Clear
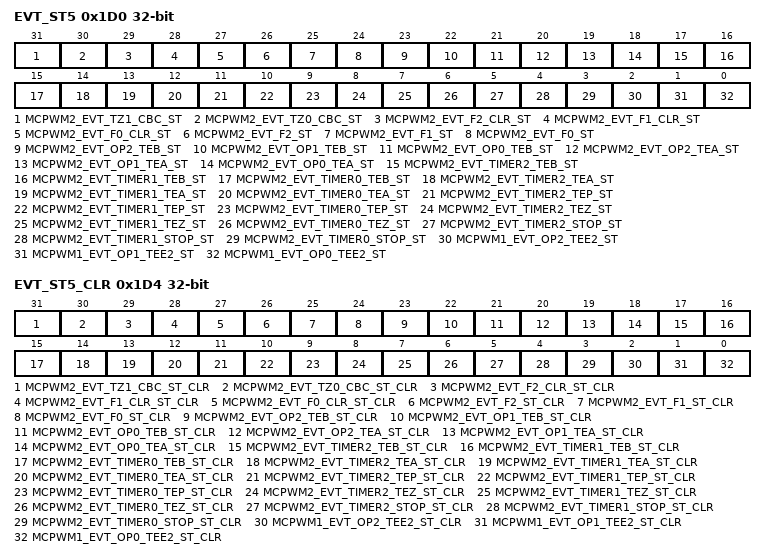
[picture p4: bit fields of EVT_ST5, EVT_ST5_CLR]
0x1D0 EVT_ST5 — Events trigger status register
  [31] MCPWM2_EVT_TZ1_CBC_ST — Represents MCPWM2_evt_tz1_cbc trigger status.\\0: Not triggered\\1: Triggered
  [30] MCPWM2_EVT_TZ0_CBC_ST — Represents MCPWM2_evt_tz0_cbc trigger status.\\0: Not triggered\\1: Triggered
  [29] MCPWM2_EVT_F2_CLR_ST — Represents MCPWM2_evt_f2_clr trigger status.\\0: Not triggered\\1: Triggered
  [28] MCPWM2_EVT_F1_CLR_ST — Represents MCPWM2_evt_f1_clr trigger status.\\0: Not triggered\\1: Triggered
  [27] MCPWM2_EVT_F0_CLR_ST — Represents MCPWM2_evt_f0_clr trigger status.\\0: Not triggered\\1: Triggered
  [26] MCPWM2_EVT_F2_ST — Represents MCPWM2_evt_f2 trigger status.\\0: Not triggered\\1: Triggered
  [25] MCPWM2_EVT_F1_ST — Represents MCPWM2_evt_f1 trigger status.\\0: Not triggered\\1: Triggered
  [24] MCPWM2_EVT_F0_ST — Represents MCPWM2_evt_f0 trigger status.\\0: Not triggered\\1: Triggered
  [23] MCPWM2_EVT_OP2_TEB_ST — Represents MCPWM2_evt_op2_teb trigger status.\\0: Not triggered\\1: Triggered
  [22] MCPWM2_EVT_OP1_TEB_ST — Represents MCPWM2_evt_op1_teb trigger status.\\0: Not triggered\\1: Triggered
  [21] MCPWM2_EVT_OP0_TEB_ST — Represents MCPWM2_evt_op0_teb trigger status.\\0: Not triggered\\1: Triggered
  [20] MCPWM2_EVT_OP2_TEA_ST — Represents MCPWM2_evt_op2_tea trigger status.\\0: Not triggered\\1: Triggered
  [19] MCPWM2_EVT_OP1_TEA_ST — Represents MCPWM2_evt_op1_tea trigger status.\\0: Not triggered\\1: Triggered
  [18] MCPWM2_EVT_OP0_TEA_ST — Represents MCPWM2_evt_op0_tea trigger status.\\0: Not triggered\\1: Triggered
  [17] MCPWM2_EVT_TIMER2_TEB_ST — Represents MCPWM2_evt_timer2_teb trigger status.\\0: Not triggered\\1: Triggered
  [16] MCPWM2_EVT_TIMER1_TEB_ST — Represents MCPWM2_evt_timer1_teb trigger status.\\0: Not triggered\\1: Triggered
  [15] MCPWM2_EVT_TIMER0_TEB_ST — Represents MCPWM2_evt_timer0_teb trigger status.\\0: Not triggered\\1: Triggered
  [14] MCPWM2_EVT_TIMER2_TEA_ST — Represents MCPWM2_evt_timer2_tea trigger status.\\0: Not triggered\\1: Triggered
  [13] MCPWM2_EVT_TIMER1_TEA_ST — Represents MCPWM2_evt_timer1_tea trigger status.\\0: Not triggered\\1: Triggered
  [12] MCPWM2_EVT_TIMER0_TEA_ST — Represents MCPWM2_evt_timer0_tea trigger status.\\0: Not triggered\\1: Triggered
  [11] MCPWM2_EVT_TIMER2_TEP_ST — Represents MCPWM2_evt_timer2_tep trigger status.\\0: Not triggered\\1: Triggered
  [10] MCPWM2_EVT_TIMER1_TEP_ST — Represents MCPWM2_evt_timer1_tep trigger status.\\0: Not triggered\\1: Triggered
  [9] MCPWM2_EVT_TIMER0_TEP_ST — Represents MCPWM2_evt_timer0_tep trigger status.\\0: Not triggered\\1: Triggered
  [8] MCPWM2_EVT_TIMER2_TEZ_ST — Represents MCPWM2_evt_timer2_tez trigger status.\\0: Not triggered\\1: Triggered
  [7] MCPWM2_EVT_TIMER1_TEZ_ST — Represents MCPWM2_evt_timer1_tez trigger status.\\0: Not triggered\\1: Triggered
  [6] MCPWM2_EVT_TIMER0_TEZ_ST — Represents MCPWM2_evt_timer0_tez trigger status.\\0: Not triggered\\1: Triggered
  [5] MCPWM2_EVT_TIMER2_STOP_ST — Represents MCPWM2_evt_timer2_stop trigger status.\\0: Not triggered\\1: Triggered
  [4] MCPWM2_EVT_TIMER1_STOP_ST — Represents MCPWM2_evt_timer1_stop trigger status.\\0: Not triggered\\1: Triggered
  [3] MCPWM2_EVT_TIMER0_STOP_ST — Represents MCPWM2_evt_timer0_stop trigger status.\\0: Not triggered\\1: Triggered
  [2] MCPWM1_EVT_OP2_TEE2_ST — Represents MCPWM1_evt_op2_tee2 trigger status.\\0: Not triggered\\1: Triggered
  [1] MCPWM1_EVT_OP1_TEE2_ST — Represents MCPWM1_evt_op1_tee2 trigger status.\\0: Not triggered\\1: Triggered
  [0] MCPWM1_EVT_OP0_TEE2_ST — Represents MCPWM1_evt_op0_tee2 trigger status.\\0: Not triggered\\1: Triggered
0x1D4 EVT_ST5_CLR wo — Events trigger status clear register
  [31] MCPWM2_EVT_TZ1_CBC_ST_CLR — Configures whether or not to clear MCPWM2_evt_tz1_cbc trigger status.\\0: Invalid, No effect\\1: Clear
  [30] MCPWM2_EVT_TZ0_CBC_ST_CLR — Configures whether or not to clear MCPWM2_evt_tz0_cbc trigger status.\\0: Invalid, No effect\\1: Clear
  [29] MCPWM2_EVT_F2_CLR_ST_CLR — Configures whether or not to clear MCPWM2_evt_f2_clr trigger status.\\0: Invalid, No effect\\1: Clear
  [28] MCPWM2_EVT_F1_CLR_ST_CLR — Configures whether or not to clear MCPWM2_evt_f1_clr trigger status.\\0: Invalid, No effect\\1: Clear
  [27] MCPWM2_EVT_F0_CLR_ST_CLR — Configures whether or not to clear MCPWM2_evt_f0_clr trigger status.\\0: Invalid, No effect\\1: Clear
  [26] MCPWM2_EVT_F2_ST_CLR — Configures whether or not to clear MCPWM2_evt_f2 trigger status.\\0: Invalid, No effect\\1: Clear
  [25] MCPWM2_EVT_F1_ST_CLR — Configures whether or not to clear MCPWM2_evt_f1 trigger status.\\0: Invalid, No effect\\1: Clear
  [24] MCPWM2_EVT_F0_ST_CLR — Configures whether or not to clear MCPWM2_evt_f0 trigger status.\\0: Invalid, No effect\\1: Clear
  [23] MCPWM2_EVT_OP2_TEB_ST_CLR — Configures whether or not to clear MCPWM2_evt_op2_teb trigger status.\\0: Invalid, No effect\\1: Clear
  [22] MCPWM2_EVT_OP1_TEB_ST_CLR — Configures whether or not to clear MCPWM2_evt_op1_teb trigger status.\\0: Invalid, No effect\\1: Clear
  [21] MCPWM2_EVT_OP0_TEB_ST_CLR — Configures whether or not to clear MCPWM2_evt_op0_teb trigger status.\\0: Invalid, No effect\\1: Clear
  [20] MCPWM2_EVT_OP2_TEA_ST_CLR — Configures whether or not to clear MCPWM2_evt_op2_tea trigger status.\\0: Invalid, No effect\\1: Clear
  [19] MCPWM2_EVT_OP1_TEA_ST_CLR — Configures whether or not to clear MCPWM2_evt_op1_tea trigger status.\\0: Invalid, No effect\\1: Clear
  [18] MCPWM2_EVT_OP0_TEA_ST_CLR — Configures whether or not to clear MCPWM2_evt_op0_tea trigger status.\\0: Invalid, No effect\\1: Clear
  [17] MCPWM2_EVT_TIMER2_TEB_ST_CLR — Configures whether or not to clear MCPWM2_evt_timer2_teb trigger status.\\0: Invalid, No effect\\1: Clear
  [16] MCPWM2_EVT_TIMER1_TEB_ST_CLR — Configures whether or not to clear MCPWM2_evt_timer1_teb trigger status.\\0: Invalid, No effect\\1: Clear
  [15] MCPWM2_EVT_TIMER0_TEB_ST_CLR — Configures whether or not to clear MCPWM2_evt_timer0_teb trigger status.\\0: Invalid, No effect\\1: Clear
  [14] MCPWM2_EVT_TIMER2_TEA_ST_CLR — Configures whether or not to clear MCPWM2_evt_timer2_tea trigger status.\\0: Invalid, No effect\\1: Clear
  [13] MCPWM2_EVT_TIMER1_TEA_ST_CLR — Configures whether or not to clear MCPWM2_evt_timer1_tea trigger status.\\0: Invalid, No effect\\1: Clear
  [12] MCPWM2_EVT_TIMER0_TEA_ST_CLR — Configures whether or not to clear MCPWM2_evt_timer0_tea trigger status.\\0: Invalid, No effect\\1: Clear
  [11] MCPWM2_EVT_TIMER2_TEP_ST_CLR — Configures whether or not to clear MCPWM2_evt_timer2_tep trigger status.\\0: Invalid, No effect\\1: Clear
  [10] MCPWM2_EVT_TIMER1_TEP_ST_CLR — Configures whether or not to clear MCPWM2_evt_timer1_tep trigger status.\\0: Invalid, No effect\\1: Clear
  [9] MCPWM2_EVT_TIMER0_TEP_ST_CLR — Configures whether or not to clear MCPWM2_evt_timer0_tep trigger status.\\0: Invalid, No effect\\1: Clear
  [8] MCPWM2_EVT_TIMER2_TEZ_ST_CLR — Configures whether or not to clear MCPWM2_evt_timer2_tez trigger status.\\0: Invalid, No effect\\1: Clear
  [7] MCPWM2_EVT_TIMER1_TEZ_ST_CLR — Configures whether or not to clear MCPWM2_evt_timer1_tez trigger status.\\0: Invalid, No effect\\1: Clear
  [6] MCPWM2_EVT_TIMER0_TEZ_ST_CLR — Configures whether or not to clear MCPWM2_evt_timer0_tez trigger status.\\0: Invalid, No effect\\1: Clear
  [5] MCPWM2_EVT_TIMER2_STOP_ST_CLR — Configures whether or not to clear MCPWM2_evt_timer2_stop trigger status.\\0: Invalid, No effect\\1: Clear
  [4] MCPWM2_EVT_TIMER1_STOP_ST_CLR — Configures whether or not to clear MCPWM2_evt_timer1_stop trigger status.\\0: Invalid, No effect\\1: Clear
  [3] MCPWM2_EVT_TIMER0_STOP_ST_CLR — Configures whether or not to clear MCPWM2_evt_timer0_stop trigger status.\\0: Invalid, No effect\\1: Clear
  [2] MCPWM1_EVT_OP2_TEE2_ST_CLR — Configures whether or not to clear MCPWM1_evt_op2_tee2 trigger status.\\0: Invalid, No effect\\1: Clear
  [1] MCPWM1_EVT_OP1_TEE2_ST_CLR — Configures whether or not to clear MCPWM1_evt_op1_tee2 trigger status.\\0: Invalid, No effect\\1: Clear
  [0] MCPWM1_EVT_OP0_TEE2_ST_CLR — Configures whether or not to clear MCPWM1_evt_op0_tee2 trigger status.\\0: Invalid, No effect\\1: Clear
